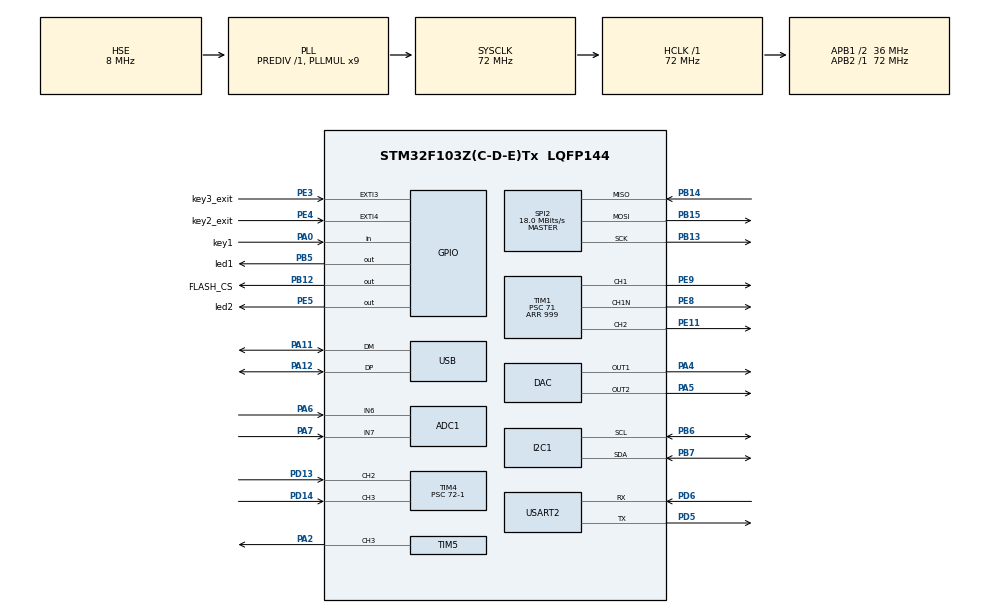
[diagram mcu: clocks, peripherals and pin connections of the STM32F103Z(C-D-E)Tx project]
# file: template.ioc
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ADC1.Channel-0\#ChannelRegularConversion=ADC_CHANNEL_6
ADC1.Channel-3\#ChannelRegularConversion=ADC_CHANNEL_7
ADC1.ContinuousConvMode=DISABLE
ADC1.ExternalTrigConv=ADC_EXTERNALTRIGCONV_T3_TRGO
ADC1.NbrOfConversion=2
ADC1.NbrOfConversionFlag=1
ADC1.Rank-0\#ChannelRegularConversion=1
ADC1.Rank-3\#ChannelRegularConversion=2
ADC1.SamplingTime-0\#ChannelRegularConversion=ADC_SAMPLETIME_71CYCLES_5
ADC1.SamplingTime-3\#ChannelRegularConversion=ADC_SAMPLETIME_71CYCLES_5
ADC1.master=1
DAC.DAC_Trigger=DAC_TRIGGER_T2_TRGO
DAC.DAC_Trigger2=DAC_TRIGGER_T2_TRGO
Dma.ADC1.2.Direction=DMA_PERIPH_TO_MEMORY
Dma.ADC1.2.Instance=DMA1_Channel1
Dma.ADC1.2.MemDataAlignment=DMA_MDATAALIGN_HALFWORD
Dma.ADC1.2.MemInc=DMA_MINC_ENABLE
Dma.ADC1.2.Mode=DMA_CIRCULAR
Dma.ADC1.2.PeriphDataAlignment=DMA_PDATAALIGN_HALFWORD
Dma.ADC1.2.PeriphInc=DMA_PINC_DISABLE
Dma.ADC1.2.Priority=DMA_PRIORITY_LOW
Dma.DAC_CH1.0.Direction=DMA_MEMORY_TO_PERIPH
Dma.DAC_CH1.0.Instance=DMA2_Channel3
Dma.DAC_CH1.0.MemDataAlignment=DMA_MDATAALIGN_HALFWORD
Dma.DAC_CH1.0.MemInc=DMA_MINC_ENABLE
Dma.DAC_CH1.0.Mode=DMA_CIRCULAR
Dma.DAC_CH1.0.PeriphDataAlignment=DMA_PDATAALIGN_HALFWORD
Dma.DAC_CH1.0.PeriphInc=DMA_PINC_DISABLE
Dma.DAC_CH1.0.Priority=DMA_PRIORITY_LOW
Dma.DAC_CH2.1.Direction=DMA_MEMORY_TO_PERIPH
Dma.DAC_CH2.1.Instance=DMA2_Channel4
Dma.DAC_CH2.1.MemDataAlignment=DMA_MDATAALIGN_HALFWORD
Dma.DAC_CH2.1.MemInc=DMA_MINC_ENABLE
Dma.DAC_CH2.1.Mode=DMA_CIRCULAR
Dma.DAC_CH2.1.PeriphDataAlignment=DMA_PDATAALIGN_HALFWORD
Dma.DAC_CH2.1.PeriphInc=DMA_PINC_DISABLE
Dma.DAC_CH2.1.Priority=DMA_PRIORITY_LOW
Dma.Request0=DAC_CH1
Dma.Request1=DAC_CH2
Dma.Request2=ADC1
Dma.Request3=TIM4_CH2
Dma.Request4=TIM4_CH3
Dma.Request5=TIM1_CH2
Dma.TIM1_CH2.5.Direction=DMA_MEMORY_TO_PERIPH
Dma.TIM1_CH2.5.Instance=DMA1_Channel3
Dma.TIM1_CH2.5.MemDataAlignment=DMA_MDATAALIGN_HALFWORD
Dma.TIM1_CH2.5.MemInc=DMA_MINC_ENABLE
Dma.TIM1_CH2.5.Mode=DMA_NORMAL
Dma.TIM1_CH2.5.PeriphDataAlignment=DMA_PDATAALIGN_HALFWORD
Dma.TIM1_CH2.5.PeriphInc=DMA_PINC_DISABLE
Dma.TIM1_CH2.5.Priority=DMA_PRIORITY_LOW
Dma.TIM4_CH2.3.Direction=DMA_PERIPH_TO_MEMORY
Dma.TIM4_CH2.3.Instance=DMA1_Channel4
Dma.TIM4_CH2.3.MemDataAlignment=DMA_MDATAALIGN_HALFWORD
Dma.TIM4_CH2.3.MemInc=DMA_MINC_ENABLE
Dma.TIM4_CH2.3.Mode=DMA_CIRCULAR
Dma.TIM4_CH2.3.PeriphDataAlignment=DMA_PDATAALIGN_HALFWORD
Dma.TIM4_CH2.3.PeriphInc=DMA_PINC_DISABLE
Dma.TIM4_CH2.3.Priority=DMA_PRIORITY_LOW
Dma.TIM4_CH3.4.Direction=DMA_PERIPH_TO_MEMORY
Dma.TIM4_CH3.4.Instance=DMA1_Channel5
Dma.TIM4_CH3.4.MemDataAlignment=DMA_MDATAALIGN_HALFWORD
Dma.TIM4_CH3.4.MemInc=DMA_MINC_ENABLE
Dma.TIM4_CH3.4.Mode=DMA_NORMAL
Dma.TIM4_CH3.4.PeriphDataAlignment=DMA_PDATAALIGN_HALFWORD
Dma.TIM4_CH3.4.PeriphInc=DMA_PINC_DISABLE
Dma.TIM4_CH3.4.Priority=DMA_PRIORITY_LOW
IWDG.Prescaler=IWDG_PRESCALER_64
IWDG.Reload=1250
Mcu.Family=STM32F1
Mcu.Name=STM32F103Z(C-D-E)Tx
Mcu.Package=LQFP144
NVIC.DMA1_Channel1_IRQn=true\:0\:0\:false\:false\:true\:false\:true\:true
NVIC.DMA1_Channel3_IRQn=true\:0\:0\:false\:false\:true\:false\:true\:true
NVIC.DMA1_Channel4_IRQn=true\:0\:0\:false\:false\:true\:false\:true\:true
NVIC.DMA1_Channel5_IRQn=true\:0\:0\:false\:false\:true\:false\:true\:true
NVIC.DMA2_Channel3_IRQn=true\:0\:0\:false\:false\:true\:false\:true\:true
NVIC.DMA2_Channel4_5_IRQn=true\:0\:0\:false\:false\:true\:false\:true\:true
NVIC.EXTI4_IRQn=true\:4\:0\:true\:false\:true\:true\:true\:true
NVIC.PriorityGroup=NVIC_PRIORITYGROUP_4
NVIC.RCC_IRQn=true\:0\:0\:false\:false\:true\:true\:false\:true
NVIC.RTC_IRQn=true\:0\:0\:false\:false\:true\:true\:true\:true
NVIC.TIM1_UP_IRQn=true\:0\:0\:false\:false\:true\:true\:true\:true
NVIC.TIM4_IRQn=true\:0\:0\:false\:false\:true\:true\:true\:true
NVIC.TIM5_IRQn=true\:0\:0\:false\:false\:true\:true\:true\:true
NVIC.USART2_IRQn=true\:0\:0\:false\:false\:true\:true\:true\:true
NVIC.USB_LP_CAN1_RX0_IRQn=true\:0\:0\:false\:false\:true\:false\:true\:true
OSC_IN.Mode=HSE-External-Oscillator
OSC_IN.Signal=RCC_OSC_IN
OSC_OUT.Mode=HSE-External-Oscillator
OSC_OUT.Signal=RCC_OSC_OUT
PA0-WKUP.GPIO_Label=key1
PA0-WKUP.GPIO_PuPd=GPIO_PULLDOWN
PA0-WKUP.Signal=GPIO_Input
PA11.Mode=Device
PA11.Signal=USB_DM
PA12.Mode=Device
PA12.Signal=USB_DP
PA13.Mode=JTAG_4_pins
PA13.Signal=SYS_JTMS-SWDIO
PA14.Mode=JTAG_4_pins
PA14.Signal=SYS_JTCK-SWCLK
PA15.Mode=JTAG_4_pins
PA15.Signal=SYS_JTDI
PA2.Signal=S_TIM5_CH3
PA4.Signal=COMP_DAC1_group
PA5.Signal=COMP_DAC2_group
PA6.Signal=ADCx_IN6
PA7.Signal=ADCx_IN7
PB12.GPIO_Label=FLASH_CS
PB12.Signal=GPIO_Output
PB13.Mode=Full_Duplex_Master
PB13.Signal=SPI2_SCK
PB14.Mode=Full_Duplex_Master
PB14.Signal=SPI2_MISO
PB15.Mode=Full_Duplex_Master
PB15.Signal=SPI2_MOSI
PB3.Mode=JTAG_4_pins
PB3.Signal=SYS_JTDO-TRACESWO
PB5.GPIO_Label=led1
PB5.GPIO_PuPd=GPIO_PULLUP
PB5.PinState=GPIO_PIN_SET
PB5.Signal=GPIO_Output
PB6.Mode=I2C
PB6.Signal=I2C1_SCL
PB7.Mode=I2C
PB7.Signal=I2C1_SDA
PC14-OSC32_IN.Mode=LSE-External-Oscillator
PC14-OSC32_IN.Signal=RCC_OSC32_IN
PC15-OSC32_OUT.Mode=LSE-External-Oscillator
PC15-OSC32_OUT.Signal=RCC_OSC32_OUT
PD13.GPIO_Mode=GPIO_MODE_INPUT
PD13.Signal=S_TIM4_CH2
PD14.Signal=S_TIM4_CH3
PD5.Mode=Asynchronous
PD5.Signal=USART2_TX
PD6.Mode=Asynchronous
PD6.Signal=USART2_RX
PE11.Signal=S_TIM1_CH2
PE3.GPIO_Label=key3_exit
PE3.GPIO_ModeDefaultEXTI=GPIO_MODE_EVT_RISING_FALLING
PE3.Signal=GPXTI3
PE4.GPIO_Label=key2_exit
PE4.GPIO_ModeDefaultEXTI=GPIO_MODE_IT_RISING
PE4.Signal=GPXTI4
PE5.GPIO_Label=led2
PE5.Signal=GPIO_Output
PE8.Mode=PWM Generation1 CH1 CH1N
PE8.Signal=TIM1_CH1N
PE9.Signal=S_TIM1_CH1
ProjectManager.HeapSize=0x200
ProjectManager.StackSize=0x400
ProjectManager.TargetToolchain=CMake
RCC.ADCPresc=RCC_ADCPCLK2_DIV6
RCC.AHBFreq_Value=72000000
RCC.APB1CLKDivider=RCC_HCLK_DIV2
RCC.APB1Freq_Value=36000000
RCC.APB1TimFreq_Value=72000000
RCC.APB2Freq_Value=72000000
RCC.APB2TimFreq_Value=72000000
RCC.HCLKFreq_Value=72000000
RCC.PLLMUL=RCC_PLL_MUL9
RCC.PLLSourceVirtual=RCC_PLLSOURCE_HSE
RCC.RTCClockSelection=RCC_RTCCLKSOURCE_LSE
RCC.SYSCLKFreq_VALUE=72000000
RCC.SYSCLKSource=RCC_SYSCLKSOURCE_PLLCLK
RCC.USBFreq_Value=48000000
RCC.USBPrescaler=RCC_USBCLKSOURCE_PLL_DIV1_5
RTC.Date=16
RTC.Hours=22
RTC.Minutes=10
RTC.Month=RTC_MONTH_AUGUST
RTC.WeekDay=RTC_WEEKDAY_FRIDAY
RTC.Year=24
SH.ADCx_IN6.0=ADC1_IN6,IN6
SH.ADCx_IN7.0=ADC1_IN7,IN7
SH.COMP_DAC1_group.0=DAC_OUT1,DAC_OUT1
SH.COMP_DAC2_group.0=DAC_OUT2,DAC_OUT2
SH.S_TIM1_CH1.0=TIM1_CH1,PWM Generation1 CH1 CH1N
SH.S_TIM1_CH2.0=TIM1_CH2,PWM Generation2 CH2
SH.S_TIM4_CH2.0=TIM4_CH2,Input_Capture2_from_TI2
SH.S_TIM4_CH3.0=TIM4_CH3,Input_Capture3_from_TI3
SH.S_TIM5_CH3.0=TIM5_CH3,PWM Generation3 CH3
SPI2.CalculateBaudRate=18.0 MBits/s
SPI2.Direction=SPI_DIRECTION_2LINES
SPI2.Mode=SPI_MODE_MASTER
SPI2.VirtualType=VM_MASTER
TIM1.AutoReloadPreload=TIM_AUTORELOAD_PRELOAD_ENABLE
TIM1.AutomaticOutput=TIM_AUTOMATICOUTPUT_ENABLE
TIM1.BreakPolarity=TIM_BREAKPOLARITY_LOW
TIM1.BreakState=TIM_BREAK_ENABLE
TIM1.Channel-PWM\ Generation1\ CH1\ CH1N=TIM_CHANNEL_1
TIM1.Channel-PWM\ Generation2\ CH2=TIM_CHANNEL_2
TIM1.DeadTime=0xac
TIM1.LockLevel=TIM_LOCKLEVEL_OFF
TIM1.OC1Preload_PWM=ENABLE
TIM1.OCIdleState_1=TIM_OCIDLESTATE_RESET
TIM1.OffStateIDLEMode=TIM_OSSI_ENABLE
TIM1.OffStateRunMode=TIM_OSSR_ENABLE
TIM1.Period=999
TIM1.Prescaler=71
TIM1.Pulse-PWM\ Generation1\ CH1\ CH1N=0
TIM1.RepetitionCounter=0
TIM2.Period=65535
TIM2.TIM_MasterOutputTrigger=TIM_TRGO_UPDATE
TIM3.AutoReloadPreload=TIM_AUTORELOAD_PRELOAD_ENABLE
TIM3.Period=999
TIM3.Prescaler=99
TIM3.TIM_MasterOutputTrigger=TIM_TRGO_UPDATE
TIM4.AutoReloadPreload=TIM_AUTORELOAD_PRELOAD_ENABLE
TIM4.Channel-Input_Capture2_from_TI2=TIM_CHANNEL_2
TIM4.Channel-Input_Capture3_from_TI3=TIM_CHANNEL_3
TIM4.ICFilter_CH2=8
TIM4.ICFilter_CH3=8
TIM4.ICPolarity_CH3=TIM_INPUTCHANNELPOLARITY_FALLING
TIM4.Period=65535
TIM4.Prescaler=72-1
TIM4.TIM_MasterOutputTrigger=TIM_TRGO_UPDATE
TIM5.Channel-PWM\ Generation3\ CH3=TIM_CHANNEL_3
TIM5.Period=65535
TIM5.Prescaler=71
USART2.VirtualMode=VM_ASYNC
USB_DEVICE.CLASS_NAME_FS=CDC
USB_DEVICE.VirtualMode=Cdc
USB_DEVICE.VirtualModeFS=Cdc_FS
VP_CRC_VS_CRC.Mode=CRC_Activate
VP_IWDG_VS_IWDG.Mode=IWDG_Activate
VP_RTC_No_RTC_Output.Mode=RTC_OUT_NO
VP_RTC_VS_RTC_Activate.Mode=RTC_Enabled
VP_RTC_VS_RTC_Calendar.Mode=RTC_Calendar
VP_TIM1_VS_ClockSourceINT.Mode=Internal
VP_TIM2_VS_ClockSourceINT.Mode=Internal
VP_TIM3_VS_ClockSourceINT.Mode=Internal
VP_TIM4_VS_ClockSourceINT.Mode=Internal
VP_TIM5_VS_ClockSourceINT.Mode=Internal
VP_USB_DEVICE_VS_USB_DEVICE_CDC_FS.Mode=CDC_FS
board=custom

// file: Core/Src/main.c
/* USER CODE BEGIN Header */
/**
 ******************************************************************************
 * @file           : main.c
 * @brief          : Main program body
 ******************************************************************************
 * @attention
 *
 * Copyright (c) 2024 STMicroelectronics.
 * All rights reserved.
 *
 * This software is licensed under terms that can be found in the LICENSE file
 * in the root directory of this software component.
 * If no LICENSE file comes with this software, it is provided AS-IS.
 *
 ******************************************************************************
 */
/* USER CODE END Header */
#include "main.h"
#include "adc.h"
#include "crc.h"
#include "dac.h"
#include "dma.h"
#include "i2c.h"
#include "iwdg.h"
#include "rtc.h"
#include "spi.h"
#include "tim.h"
#include "usart.h"
#include "usb_device.h"
#include "gpio.h"

void SystemClock_Config(void);

int main(void)
{

  /* MCU Configuration--------------------------------------------------------*/

  /* Reset of all peripherals, Initializes the Flash interface and the Systick. */
  HAL_Init();

  /* Configure the system clock */
  SystemClock_Config();

  /* USER CODE BEGIN SysInit */
	GPIO_Hal_USB_Reset();
  /* USER CODE END SysInit */

  /* Initialize all configured peripherals */
  MX_GPIO_Init();
  MX_DMA_Init();
  MX_USART2_UART_Init();
  MX_USB_DEVICE_Init();
  MX_I2C1_Init();
  MX_CRC_Init();
  MX_SPI2_Init();
  MX_RTC_Init();
  MX_DAC_Init();
  MX_TIM2_Init();
  MX_TIM4_Init();
  MX_ADC1_Init();
  MX_TIM3_Init();
  MX_TIM1_Init();
  MX_IWDG_Init();
  MX_TIM5_Init();
  /* USER CODE BEGIN 2 */

	printf("hello every one this is template to test!\n");
	USART_Hal_Test();  //little test usart
//	I2C_Hal_Test();    //little test i2c
//	SPI_Hal_Test();    //little test spi
//	CRC_Hal_Test();    //little test crc
	DAC_Hal_Test();	   //little test dac
	PWM_Hal_Test();
  /* USER CODE END 2 */

  /* Infinite loop */
	while (1) {

    /* USER CODE BEGIN 3 */
		IWDG_Hal_Test();//little test IWDG,if we don't reflash this fun in setting time ,the iwdg will reboot the sys
		//	GPIO_Hal_Test(); 	//little test the GPIO in key and led on the board
		//  USB_CDC_Hal_Test(); //little test the CDC USB
		//	RTC_Hal_Test();
		ADC_DMA_Hal_Test();
		PWMCapture_DMA_Hal_Test();
	}

  /* USER CODE END 3 */
}

void SystemClock_Config(void)
{
  RCC_OscInitTypeDef RCC_OscInitStruct = {0};
  RCC_ClkInitTypeDef RCC_ClkInitStruct = {0};
  RCC_PeriphCLKInitTypeDef PeriphClkInit = {0};

  /** Initializes the RCC Oscillators according to the specified parameters
  * in the RCC_OscInitTypeDef structure.
  */
  RCC_OscInitStruct.OscillatorType = RCC_OSCILLATORTYPE_LSI|RCC_OSCILLATORTYPE_HSE
                              |RCC_OSCILLATORTYPE_LSE;
  RCC_OscInitStruct.HSEState = RCC_HSE_ON;
  RCC_OscInitStruct.HSEPredivValue = RCC_HSE_PREDIV_DIV1;
  RCC_OscInitStruct.LSEState = RCC_LSE_ON;
  RCC_OscInitStruct.HSIState = RCC_HSI_ON;
  RCC_OscInitStruct.LSIState = RCC_LSI_ON;
  RCC_OscInitStruct.PLL.PLLState = RCC_PLL_ON;
  RCC_OscInitStruct.PLL.PLLSource = RCC_PLLSOURCE_HSE;
  RCC_OscInitStruct.PLL.PLLMUL = RCC_PLL_MUL9;
  if (HAL_RCC_OscConfig(&RCC_OscInitStruct) != HAL_OK)
  {
    Error_Handler();
  }

  /** Initializes the CPU, AHB and APB buses clocks
  */
  RCC_ClkInitStruct.ClockType = RCC_CLOCKTYPE_HCLK|RCC_CLOCKTYPE_SYSCLK
                              |RCC_CLOCKTYPE_PCLK1|RCC_CLOCKTYPE_PCLK2;
  RCC_ClkInitStruct.SYSCLKSource = RCC_SYSCLKSOURCE_PLLCLK;
  RCC_ClkInitStruct.AHBCLKDivider = RCC_SYSCLK_DIV1;
  RCC_ClkInitStruct.APB1CLKDivider = RCC_HCLK_DIV2;
  RCC_ClkInitStruct.APB2CLKDivider = RCC_HCLK_DIV1;

  if (HAL_RCC_ClockConfig(&RCC_ClkInitStruct, FLASH_LATENCY_2) != HAL_OK)
  {
    Error_Handler();
  }
  PeriphClkInit.PeriphClockSelection = RCC_PERIPHCLK_RTC|RCC_PERIPHCLK_ADC
                              |RCC_PERIPHCLK_USB;
  PeriphClkInit.RTCClockSelection = RCC_RTCCLKSOURCE_LSE;
  PeriphClkInit.AdcClockSelection = RCC_ADCPCLK2_DIV6;
  PeriphClkInit.UsbClockSelection = RCC_USBCLKSOURCE_PLL_DIV1_5;
  if (HAL_RCCEx_PeriphCLKConfig(&PeriphClkInit) != HAL_OK)
  {
    Error_Handler();
  }
}

void Error_Handler(void)
{
	__disable_irq();
	while (1) {
	}
}
